VERSION ""

NS_ :

BS_:
BU_: ZeroGen2
BO_ 448 DASH_STATUS: 0 ZeroGen2
   SG_ DashTimeHours : 16|8@1+ (1,0) [0|255] "hours" ZeroGen2
   SG_ DashTimeMinutes : 24|8@1+ (1,0) [0|255] "minutes" ZeroGen2
   SG_ DashTimeSeconds : 32|8@1+ (1,0) [0|255] "seconds" ZeroGen2
   SG_ NumberOfCanMessageSets : 40|24@1+ (1,0) [0|16777215] "count" ZeroGen2

BO_ 385 CONTROLLER_SPEED_TORQUE: 0 ZeroGen2

BO_ 392 BMS_PACK_STATUS: 0 ZeroGen2
   SG_ CellBalance : 47|8@0+ (0,0) [0|1] "balance" ZeroGen2
   SG_ ChargeCycles : 24|16@1+ (1,0) [0|65535] "cycles" ZeroGen2

BO_ 402 PACK_STATUS2: 0 ZeroGen2

BO_ 960 DASH_ODO_TO_DASH: 0 ZeroGen2
   SG_ ODO1 : 0|24@1+ (0.1,0) [0|1677721.5] "km" ZeroGen2

BO_ 704 ODO_FROM_DASH: 0 ZeroGen2
   SG_ ODO2 : 0|24@1+ (0.1,0) [0|1677721.5] "km" ZeroGen2

BO_ 517 CONTROLLER_DRIVE_CONTROL: 0 ZeroGen2

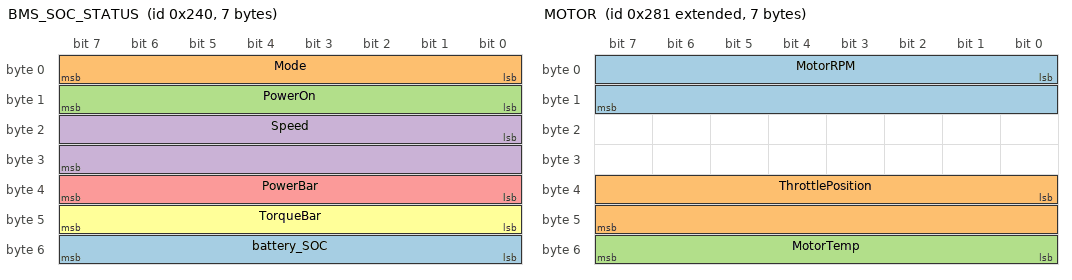
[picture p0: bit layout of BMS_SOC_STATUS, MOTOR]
BO_ 576 BMS_SOC_STATUS: 7 ZeroGen2
   SG_ battery_SOC : 55|8@0+ (1,0) [0|1] "" ZeroGen2
   SG_ Mode : 7|8@0+ (1,0) [0|1] "mode" ZeroGen2
   SG_ PowerOn : 15|8@0+ (1,0) [0|1] "" ZeroGen2
   SG_ Speed : 16|16@1+ (0.01,0) [0|65535] "km/h" ZeroGen2
   SG_ PowerBar : 39|8@0+ (1,0) [0|1] "" ZeroGen2
   SG_ TorqueBar : 47|8@0+ (1,0) [0|1] "" ZeroGen2

BO_ 648 CONTROLLER_RPM_THROTTLE_MOT_TEMP: 0 ZeroGen2
   SG_ MaxAh : 47|8@0+ (1,0) [0|1] "MaxAh" ZeroGen2
   SG_ Power : 0|16@1+ (1,0) [0|65535] "W" ZeroGen2

BO_ 649 CONTROLLER_RPM_THROTTLE_MOT_TEMP435: 0 ZeroGen2

BO_ 776 BMS_PACK_STATS: 0 ZeroGen2

BO_ 777 BMS1_PACK_STATS: 0 ZeroGen2

BO_ 778 BMS1_PACK_STATS556: 0 ZeroGen2

BO_ 832 BIKE_ERROR_STATUS: 0 ZeroGen2
   SG_ ERROR_CODE : 55|8@0+ (1,0) [0|1] "code" ZeroGen2
   SG_ Trip1 : 0|16@1+ (0.01,0) [0|65535] "units" ZeroGen2

BO_ 897 CONTROLLER_TEMP_DIGITAL_IN_18: 0 ZeroGen2
   SG_ ControllerTemp : 23|8@0+ (1,0) [0|1] "C" ZeroGen2

BO_ 904 BMS_CELL_VOLTAGE: 0 ZeroGen2
   SG_ Voltage : 0|24@1+ (1,0) [0|16777215] "V" ZeroGen2
   SG_ Vbatt : 24|24@1+ (1,0) [0|16777215] "V" ZeroGen2

BO_ 1032 BMS_PACK_ACTIVE_DATA: 0 ZeroGen2
   SG_ batteryAmps : 39|16@0+ (1,0) [0|1] "A" ZeroGen2
   SG_ temperatureMax : 15|8@0+ (1,0) [0|1] "°C" ZeroGen2
   SG_ temperatureMin : 23|8@0+ (1,0) [0|1] "°C" ZeroGen2
   SG_ charger_voltage : 31|8@0+ (1,0) [0|1] "V" ZeroGen2
   SG_ charger_on : 24|1@0+ (1,0) [0|1] "" ZeroGen2

BO_ 1033 BMS1_PACK_ACTIVE_DATA: 0 ZeroGen2

BO_ 1088 DASH_STATUS2: 0 ZeroGen2
   SG_ Trip2 : 0|24@1+ (1,0) [0|16777215] "km" ZeroGen2
   SG_ Range : 32|16@1+ (1,0) [0|65535] "km" ZeroGen2
   SG_ MotorTemperature : 48|16@1+ (1,0) [0|65535] "°C" ZeroGen2

BO_ 1160 BMS_PACK_TEMP_DATA: 0 ZeroGen2

BO_ 1286 BMS_CONTROL: 0 ZeroGen2

BO_ 1288 BMS_PACK_TIME: 0 ZeroGen2
   SG_ BMS_PACK_TIMESig452 : 39|16@0+ (1,0) [0|1] "" ZeroGen2

BO_ 1289 BMS1_PACK_TIME: 0 ZeroGen2

BO_ 1344 DASH_STATUS3: 0 ZeroGen2
   SG_ ChargeMinutesToGo : 0|16@1+ (1,0) [0|65535] "min" ZeroGen2
   SG_ MomentaryWhPerKm : 16|16@1+ (0.01,0) [0|65535] "Wh/km" ZeroGen2
   SG_ TripWhPerKm : 32|16@1+ (0.01,0) [0|65535] "Wh/km" ZeroGen2
   SG_ LifeWhPerKm : 48|16@1+ (0.01,0) [0|65535] "Wh/km" ZeroGen2

BO_ 2147484050 BMS_PACK_STATUS2: 0 ZeroGen2

BO_ 2147484166 BMS_PACK_STATUS3: 0 ZeroGen2
   SG_ ChargeVoltage3 : 31|8@0+ (1,0) [0|1] "" ZeroGen2
   SG_ ChargeVoltage4 : 39|8@0+ (1,0) [0|1] "" ZeroGen2
   SG_ ChargeVoltage5 : 47|8@0+ (1,0) [0|1] "" ZeroGen2

BO_ 2147484289 MOTOR: 7 ZeroGen2
   SG_ MotorRPM : 0|16@1+ (1,0) [0|65535] "rpm" ZeroGen2
   SG_ ThrottlePosition : 32|16@1+ (1,0) [0|65535] "unit" ZeroGen2
   SG_ MotorTemp : 55|8@0+ (1,0) [0|1] "°C" ZeroGen2

BO_ 704 test_odo: 0 ZeroGen2

BO_ 518 BMS_CHARGER: 0 ZeroGen2
   SG_ ChargerVoltage : 24|24@1+ (0.001,0) [0|65535] "V" ZeroGen2

BA_DEF_ BO_ "GenMsgBackgroundColor" STRING ;
BA_DEF_ BO_ "GenMsgForegroundColor" STRING ;
BA_ "GenMsgForegroundColor" BO_ 704 "#ff0000";
BA_DEF_DEF_ "GenMsgBackgroundColor" "#ffffff";
BA_DEF_DEF_ "GenMsgForegroundColor" "#000000";
CM_ SG_ 448 CanMessageSets5 "[5]_+_258_*_[6]_+_256_*_256_[7]";
CM_ SG_ 392 ChargeCycle3 "[3]_+_256_*_[4]";
CM_ SG_ 392 ChargeCycle4 "[3]_+_256_*_[4]";
CM_ SG_ 576 Mode "2_Sport_3_Eco_4_Custom";
CM_ SG_ 576 PowerOn "0_charging_15_run";
CM_ SG_ 576 Speed2 "[2]_*_0.01_+_[3]_*_2.56";
CM_ SG_ 576 Speed3 "[2]_*_0.01_+_[3]_*_2.56";
CM_ SG_ 576 TorqueBar "TorqueBar_>_128_then_TB_=_0.1_*_(TorqueBar_-_255)";
CM_ SG_ 648 MaxAh "fixed_at_114?";
CM_ SG_ 648 PowerWatts0 "[0]_+_256_*_[1]";
CM_ SG_ 648 PowerWatts1 "[0]_+_256_*_[1]";
CM_ SG_ 832 Trip1_0 "[0]_*_0.01_+_[1]_*_2.56";
CM_ SG_ 832 Trip1_1 "[0]_*_0.01_+_[1]_*_2.56";
CM_ SG_ 832 RPM4 "[4]_+_256_*_[5]";
CM_ SG_ 832 RPM5 "[4]_+_256_*_[5]";
CM_ SG_ 904 VBatt3 "0.001_*_[3]_+_0.256_*_[4]_+_65.535_*_[5]";
CM_ SG_ 904 VBatt4 "0.001_*_[3]_+_0.256_*_[4]_+_65.535_*_[5]";
CM_ SG_ 904 VBatt5 "0.001_*_[3]_+_0.256_*_[4]_+_65.535_*_[5]";
CM_ SG_ 1088 Trip2_0 "[0]_*_0.1_+_[1]_*_2.56_+_[2]_*_655.35";
CM_ SG_ 1088 Trip2_1 "[0]_*_0.1_+_[1]_*_2.56_+_[2]_*_655.35";
CM_ SG_ 1088 Trip2_2 "[0]_*_0.1_+_[1]_*_2.56_+_[2]_*_655.35";
CM_ SG_ 1088 Range4 "[4]_*_0.01_+_[5]_*_2.56";
CM_ SG_ 1088 Range5 "[4]_*_0.01_+_[5]_*_2.56";
CM_ SG_ 1088 MotorTemp6 "[6]_*_0.01_+_[7]_*_2.56";
CM_ SG_ 1088 MotorTemp7 "[6]_*_0.01_+_[7]_*_2.56";
CM_ SG_ 1344 ChargeToGo0 "[0]_+_256_+_[1]";
CM_ SG_ 1344 ChargeToGo1 "[0]_+_256_+_[1]";
CM_ SG_ 1344 MomentryWhPerKm2 "[2]_*_0.01_+_[3]_*_2.56";
CM_ SG_ 1344 MomentryWhPerKm3 "[2]_*_0.01_+_[3]_*_2.56";
CM_ SG_ 1344 TripPerKm4 "[4]_*_0.01_+_[5]_*_2.56";
CM_ SG_ 1344 TripPerKm5 "[4]_*_0.01_+_[5]_*_2.56";
CM_ SG_ 1344 LifeWhPerKm6 "[6]_*_0.01_+_[7]_*_2.56";
CM_ SG_ 1344 LifeWhPerKm7 "[6]_*_0.01_+_[7]_*_2.56";
CM_ SG_ 2147484166 ChargeVoltage3 "[3]_*_0.001_+_[4]_*_0.256_+_[5]_*_65.535_charger_voltage_in_Mv_divide_by_100_to_get_volts";
CM_ SG_ 2147484166 ChargeVoltage4 "[3]_*_0.001_+_[4]_*_0.256_+_[5]_*_65.535_charger_voltage_in_Mv_divide_by_100_to_get_volts";
CM_ SG_ 2147484166 ChargeVoltage5 "[3]_*_0.001_+_[4]_*_0.256_+_[5]_*_65.535_charger_voltage_in_Mv_divide_by_100_to_get_volts";
CM_ SG_ 2147484289 Motor0 "[0]_+_256_*_[1]";
CM_ SG_ 2147484289 Motor1 "[0]_+_256_*_[1]_same_as_0x0340_[4]_[5]";
CM_ SG_ 2147484289 ThrottlePosition4 "[4]_+_256_*_[5]";
CM_ SG_ 2147484289 ThrottlePosition5 "[4]_+_256_*_[5]";
